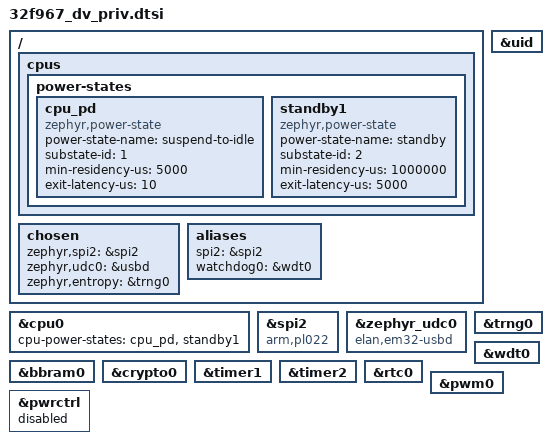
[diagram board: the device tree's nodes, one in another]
/*
 * SPDX-FileCopyrightText: 2026 ELAN Microelectronics Corp.
 * SPDX-License-Identifier: Apache-2.0
 */

/*
 * Board-specific CPU power state wiring.
 *
 * Per EM32F967 spec, the PWRCTRL PD_SW field selects power domain switch mode
 * (Active/CPU/Standby1/GHM/Standby2). We expose the Zephyr PM states for
 * PDSW1/PDSW2/PDSW4 here.
 */

&cpu0 {
	cpu-power-states = <&cpu_pd &standby1>;
};

/ {
	cpus {
		power-states {
			/* PDSW1 - CPU Power Down (suspend-to-idle) */
			cpu_pd: cpu_pd {
				compatible = "zephyr,power-state";
				power-state-name = "suspend-to-idle";
				substate-id = <1>;
				min-residency-us = <5000>; /* 1 second */
				exit-latency-us = <10>;
			};

			/* PDSW2 - Standby1 (standby with selective RAM retention) */
			standby1: standby1 {
				compatible = "zephyr,power-state";
				power-state-name = "standby";
				substate-id = <2>;
				min-residency-us = <1000000>; /* 1 second */
				exit-latency-us = <5000>;
			};

		};
	};
};

/ {
	chosen {
		zephyr,spi2 = &spi2;
		zephyr,udc0 = &usbd;
		zephyr,entropy = &trng0;
	};

	aliases {
		spi2 = &spi2;
		watchdog0 = &wdt0;
	};
};

&spi2 {
	compatible = "arm,pl022";
	status = "okay";
};

&zephyr_udc0 {
	compatible = "elan,em32-usbd";
	status = "okay";
};

&uid {
	status = "okay";
};

&bbram0 {
	status = "okay";
};

&trng0 {
	status = "okay";
};

&wdt0 {
	status = "okay";
};

&crypto0 {
	status = "okay";
};

/* Enable Timer controllers */
&timer1 {
	status = "okay";
};

&timer2 {
	status = "okay";
};

/* Enable RTC */
&rtc0 {
	status = "okay";
};

/* Enable PWM Controller - PWMB N output on PA3 */
&pwm0 {
	status = "okay";
};

&pwrctrl {
	status = "disabled";
};
